AUTOSAR XML (schema 4-0-3)
package /ComponentTypes
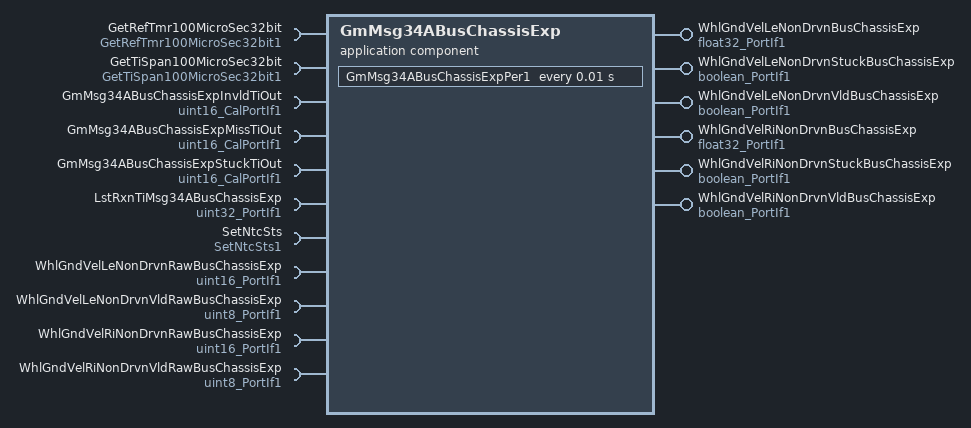
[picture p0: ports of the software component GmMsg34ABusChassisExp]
  application sw component type GmMsg34ABusChassisExp
    6 x provide port:
      WhlGndVelLeNonDrvnBusChassisExp: nonqueued-sender-com-spec{data-element=Val, init-value=0}, provided-interface=float32_PortIf1
      WhlGndVelLeNonDrvnStuckBusChassisExp: nonqueued-sender-com-spec{data-element=Logl, init-value=0}, provided-interface=boolean_PortIf1
      WhlGndVelLeNonDrvnVldBusChassisExp: nonqueued-sender-com-spec{data-element=Logl, init-value=0}, provided-interface=boolean_PortIf1
      WhlGndVelRiNonDrvnBusChassisExp: nonqueued-sender-com-spec{data-element=Val, init-value=0}, provided-interface=float32_PortIf1
      WhlGndVelRiNonDrvnStuckBusChassisExp: nonqueued-sender-com-spec{data-element=Logl, init-value=0}, provided-interface=boolean_PortIf1
      WhlGndVelRiNonDrvnVldBusChassisExp: nonqueued-sender-com-spec{data-element=Logl, init-value=0}, provided-interface=boolean_PortIf1
    11 x require port:
      GetRefTmr100MicroSec32bit: required-interface=GetRefTmr100MicroSec32bit1
      GetTiSpan100MicroSec32bit: required-interface=GetTiSpan100MicroSec32bit1
      GmMsg34ABusChassisExpInvldTiOut: parameter-require-com-spec{init-value=1000, parameter=Val}, required-interface=uint16_CalPortIf1
      GmMsg34ABusChassisExpMissTiOut: parameter-require-com-spec{init-value=500, parameter=Val}, required-interface=uint16_CalPortIf1
      GmMsg34ABusChassisExpStuckTiOut: parameter-require-com-spec{init-value=500, parameter=Val}, required-interface=uint16_CalPortIf1
      LstRxnTiMsg34ABusChassisExp: nonqueued-receiver-com-spec{data-element=Val, filter=data-filter-type=ALWAYS, init-value=0}, required-interface=uint32_PortIf1
      SetNtcSts: required-interface=SetNtcSts1
      WhlGndVelLeNonDrvnRawBusChassisExp: nonqueued-receiver-com-spec{data-element=Val, filter=data-filter-type=ALWAYS, init-value=0}, required-interface=uint16_PortIf1
      WhlGndVelLeNonDrvnVldRawBusChassisExp: nonqueued-receiver-com-spec{data-element=Val, filter=data-filter-type=ALWAYS, init-value=0}, required-interface=uint8_PortIf1
      WhlGndVelRiNonDrvnRawBusChassisExp: nonqueued-receiver-com-spec{data-element=Val, filter=data-filter-type=ALWAYS, init-value=0}, required-interface=uint16_PortIf1
      WhlGndVelRiNonDrvnVldRawBusChassisExp: nonqueued-receiver-com-spec{data-element=Val, filter=data-filter-type=ALWAYS, init-value=0}, required-interface=uint8_PortIf1
    behavior GmMsg34ABusChassisExp_InternalBehavior: data-type-mapping=Nexteer
      ar-typed-per-instance-memorys:
        6 x data, all with sw-calibration-access=READ-ONLY:
          GmMsg34ABusChassisExpPrevWhlGndVelLeNonDrvn: type=uint16
          GmMsg34ABusChassisExpPrevWhlGndVelRiNonDrvn: type=uint16
          GmMsg34ABusChassisExpWhlGndVelLeNonDrvnInvldTi: type=uint32
          GmMsg34ABusChassisExpWhlGndVelLeNonDrvnStuckTi: type=uint32
          GmMsg34ABusChassisExpWhlGndVelRiNonDrvnInvldTi: type=uint32
          GmMsg34ABusChassisExpWhlGndVelRiNonDrvnStuckTi: type=uint32
      timing event TMT_GM0C9HSPer1: start-on-event=GmMsg34ABusChassisExpPer1, period=0.01
      runnable GmMsg34ABusChassisExpPer1
        data-receive-point-by-arguments:
          5 x access:
            REC_HiSpdWhlGndVelLeDrvn_Val: accessed-variable=WhlGndVelLeNonDrvnRawBusChassisExp.Val
            REC_HiSpdWhlGndVelLeDrvnVld_Val: accessed-variable=WhlGndVelLeNonDrvnVldRawBusChassisExp.Val
            REC_HiSpdWhlGndVelRiDrvn_Val: accessed-variable=WhlGndVelRiNonDrvnRawBusChassisExp.Val
            REC_HiSpdWhlGndVelRiDrvnVld_Val: accessed-variable=WhlGndVelRiNonDrvnVldRawBusChassisExp.Val
            REC_Msg348HSLstRxnTi_Val: accessed-variable=LstRxnTiMsg34ABusChassisExp.Val
        data-send-points:
          6 x access:
            SEND_GM348HSWhlGndVelLeDrvn_Val: accessed-variable=WhlGndVelLeNonDrvnBusChassisExp.Val
            SEND_GM348HSWhlGndVelLeDrvnVld_Logl: accessed-variable=WhlGndVelLeNonDrvnVldBusChassisExp.Logl
            SEND_GM348HSWhlGndVelRiDrvn_Val: accessed-variable=WhlGndVelRiNonDrvnBusChassisExp.Val
            SEND_GM348HSWhlGndVelRiDrvnVld_Logl: accessed-variable=WhlGndVelRiNonDrvnVldBusChassisExp.Logl
            SEND_WhlGndVelLeNonDrvnStuckBusChassisExp_Logl: accessed-variable=WhlGndVelLeNonDrvnStuckBusChassisExp.Logl
            SEND_WhlGndVelRiNonDrvnStuckBusChassisExp_Logl: accessed-variable=WhlGndVelRiNonDrvnStuckBusChassisExp.Logl
        sync call SC_GetRefTmr100MicroSec32bit_Oper: operation=GetRefTmr100MicroSec32bit.Oper, timeout=0
        sync call SC_GetTiSpan100MicroSec32bit_Oper: operation=GetTiSpan100MicroSec32bit.Oper, timeout=0
        sync call SC_SetNtcSts_Oper: operation=SetNtcSts.Oper, timeout=0
  swc implementation GmMsg34ABusChassisExp_Implementation: behavior=GmMsg34ABusChassisExp_InternalBehavior
    code-descriptors:
      code Default: artifact-descriptors=autosar-engineering-object={short-label=Default, category=SWSRC}
